# MSP432E411Y register map
Vendor: Texas Instruments; File version: 3.200
CPU: CM4 r1p2, little endian, no MPU, no FPU, 0x3 interrupt priority bits, 0x0 interrupts
Registers are 32-bit, read-write, no defined reset value unless marked. A register's access mark holds for its fields unless they carry their own. Offsets are from the block's base; [hi:lo] are bit positions; <NAME> marks a mode.

## UART0 — Register map for UART0 peripheral
Base 0x4000C000; register names take the prefix UART0
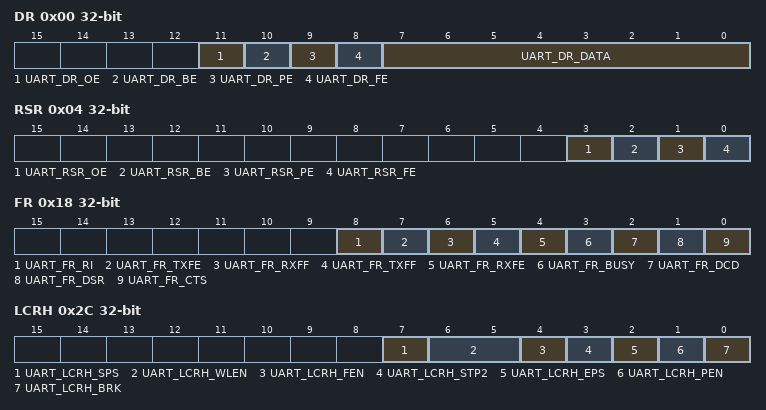
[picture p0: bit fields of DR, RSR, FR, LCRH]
0x00 DR — UART Data
  [11] UART_DR_OE — UART Overrun Error
  [10] UART_DR_BE — UART Break Error
  [9] UART_DR_PE — UART Parity Error
  [8] UART_DR_FE — UART Framing Error
  [7:0] UART_DR_DATA — Data Transmitted or Received
0x04 RSR — UART Receive Status/Error Clear
  [3] UART_RSR_OE — UART Overrun Error
  [2] UART_RSR_BE — UART Break Error
  [1] UART_RSR_PE — UART Parity Error
  [0] UART_RSR_FE — UART Framing Error
0x04 ECR (UART_ALT view) — UART Receive Status/Error Clear
  [7:0] UART_ECR_DATA — Error Clear
0x18 FR — UART Flag
  [8] UART_FR_RI — Ring Indicator
  [7] UART_FR_TXFE — UART Transmit FIFO Empty
  [6] UART_FR_RXFF — UART Receive FIFO Full
  [5] UART_FR_TXFF — UART Transmit FIFO Full
  [4] UART_FR_RXFE — UART Receive FIFO Empty
  [3] UART_FR_BUSY — UART Busy
  [2] UART_FR_DCD — Data Carrier Detect
  [1] UART_FR_DSR — Data Set Ready
  [0] UART_FR_CTS — Clear To Send
0x20 ILPR — UART IrDA Low-Power Register
  [7:0] UART_ILPR_ILPDVSR — IrDA Low-Power Divisor
0x24 IBRD — UART Integer Baud-Rate Divisor
  [15:0] UART_IBRD_DIVINT — Integer Baud-Rate Divisor
0x28 FBRD — UART Fractional Baud-Rate Divisor
  [5:0] UART_FBRD_DIVFRAC — Fractional Baud-Rate Divisor
0x2C LCRH — UART Line Control
  [7] UART_LCRH_SPS — UART Stick Parity Select
  [6:5] UART_LCRH_WLEN — UART Word Length
    0=5 bits (default); 1=6 bits; 2=7 bits; 3=8 bits
  [4] UART_LCRH_FEN — UART Enable FIFOs
  [3] UART_LCRH_STP2 — UART Two Stop Bits Select
  [2] UART_LCRH_EPS — UART Even Parity Select
  [1] UART_LCRH_PEN — UART Parity Enable
  [0] UART_LCRH_BRK — UART Send Break
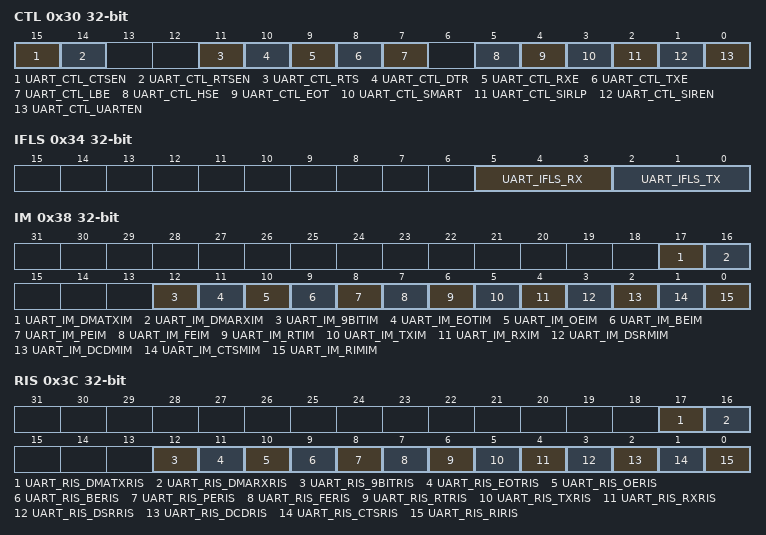
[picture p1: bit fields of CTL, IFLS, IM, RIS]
0x30 CTL — UART Control
  [15] UART_CTL_CTSEN — Enable Clear To Send
  [14] UART_CTL_RTSEN — Enable Request to Send
  [11] UART_CTL_RTS — Request to Send
  [10] UART_CTL_DTR — Data Terminal Ready
  [9] UART_CTL_RXE — UART Receive Enable
  [8] UART_CTL_TXE — UART Transmit Enable
  [7] UART_CTL_LBE — UART Loop Back Enable
  [5] UART_CTL_HSE — High-Speed Enable
  [4] UART_CTL_EOT — End of Transmission
  [3] UART_CTL_SMART — ISO 7816 Smart Card Support
  [2] UART_CTL_SIRLP — UART SIR Low-Power Mode
  [1] UART_CTL_SIREN — UART SIR Enable
  [0] UART_CTL_UARTEN — UART Enable
0x34 IFLS — UART Interrupt FIFO Level Select
  [5:3] UART_IFLS_RX — UART Receive Interrupt FIFO Level Select
    0=UART_IFLS_RX1_8 (RX FIFO >= 1/8 full); 1=UART_IFLS_RX2_8 (RX FIFO >= 1/4 full); 2=UART_IFLS_RX4_8 (RX FIFO >= 1/2 full (default)); 3=UART_IFLS_RX6_8 (RX FIFO >= 3/4 full); 4=UART_IFLS_RX7_8 (RX FIFO >= 7/8 full)
  [2:0] UART_IFLS_TX — UART Transmit Interrupt FIFO Level Select
    0=UART_IFLS_TX1_8 (TX FIFO <= 1/8 full); 1=UART_IFLS_TX2_8 (TX FIFO <= 1/4 full); 2=UART_IFLS_TX4_8 (TX FIFO <= 1/2 full (default)); 3=UART_IFLS_TX6_8 (TX FIFO <= 3/4 full); 4=UART_IFLS_TX7_8 (TX FIFO <= 7/8 full)
0x38 IM — UART Interrupt Mask
  [17] UART_IM_DMATXIM — Transmit DMA Interrupt Mask
  [16] UART_IM_DMARXIM — Receive DMA Interrupt Mask
  [12] UART_IM_9BITIM — 9-Bit Mode Interrupt Mask
  [11] UART_IM_EOTIM — End of Transmission Interrupt Mask
  [10] UART_IM_OEIM — UART Overrun Error Interrupt Mask
  [9] UART_IM_BEIM — UART Break Error Interrupt Mask
  [8] UART_IM_PEIM — UART Parity Error Interrupt Mask
  [7] UART_IM_FEIM — UART Framing Error Interrupt Mask
  [6] UART_IM_RTIM — UART Receive Time-Out Interrupt Mask
  [5] UART_IM_TXIM — UART Transmit Interrupt Mask
  [4] UART_IM_RXIM — UART Receive Interrupt Mask
  [3] UART_IM_DSRMIM — UART Data Set Ready Modem Interrupt Mask
  [2] UART_IM_DCDMIM — UART Data Carrier Detect Modem Interrupt Mask
  [1] UART_IM_CTSMIM — UART Clear to Send Modem Interrupt Mask
  [0] UART_IM_RIMIM — UART Ring Indicator Modem Interrupt Mask
0x3C RIS — UART Raw Interrupt Status
  [17] UART_RIS_DMATXRIS — Transmit DMA Raw Interrupt Status
  [16] UART_RIS_DMARXRIS — Receive DMA Raw Interrupt Status
  [12] UART_RIS_9BITRIS — 9-Bit Mode Raw Interrupt Status
  [11] UART_RIS_EOTRIS — End of Transmission Raw Interrupt Status
  [10] UART_RIS_OERIS — UART Overrun Error Raw Interrupt Status
  [9] UART_RIS_BERIS — UART Break Error Raw Interrupt Status
  [8] UART_RIS_PERIS — UART Parity Error Raw Interrupt Status
  [7] UART_RIS_FERIS — UART Framing Error Raw Interrupt Status
  [6] UART_RIS_RTRIS — UART Receive Time-Out Raw Interrupt Status
  [5] UART_RIS_TXRIS — UART Transmit Raw Interrupt Status
  [4] UART_RIS_RXRIS — UART Receive Raw Interrupt Status
  [3] UART_RIS_DSRRIS — UART Data Set Ready Modem Raw Interrupt Status
  [2] UART_RIS_DCDRIS — UART Data Carrier Detect Modem Raw Interrupt Status
  [1] UART_RIS_CTSRIS — UART Clear to Send Modem Raw Interrupt Status
  [0] UART_RIS_RIRIS — UART Ring Indicator Modem Raw Interrupt Status
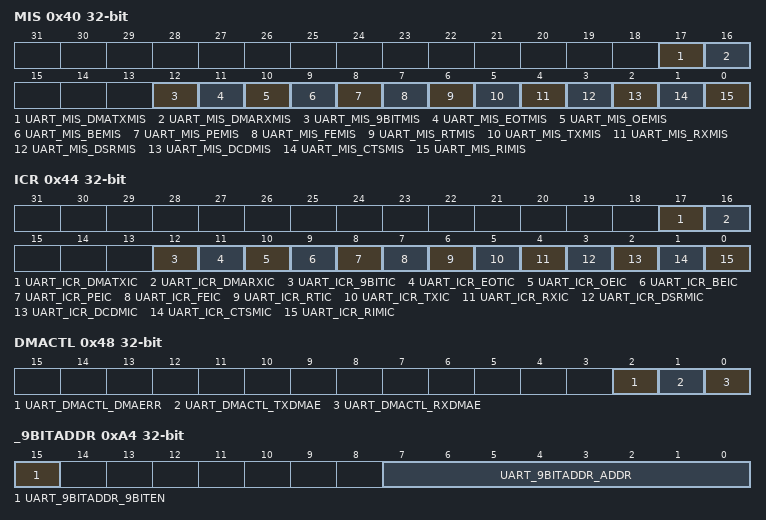
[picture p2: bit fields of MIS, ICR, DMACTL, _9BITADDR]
0x40 MIS — UART Masked Interrupt Status
  [17] UART_MIS_DMATXMIS — Transmit DMA Masked Interrupt Status
  [16] UART_MIS_DMARXMIS — Receive DMA Masked Interrupt Status
  [12] UART_MIS_9BITMIS — 9-Bit Mode Masked Interrupt Status
  [11] UART_MIS_EOTMIS — End of Transmission Masked Interrupt Status
  [10] UART_MIS_OEMIS — UART Overrun Error Masked Interrupt Status
  [9] UART_MIS_BEMIS — UART Break Error Masked Interrupt Status
  [8] UART_MIS_PEMIS — UART Parity Error Masked Interrupt Status
  [7] UART_MIS_FEMIS — UART Framing Error Masked Interrupt Status
  [6] UART_MIS_RTMIS — UART Receive Time-Out Masked Interrupt Status
  [5] UART_MIS_TXMIS — UART Transmit Masked Interrupt Status
  [4] UART_MIS_RXMIS — UART Receive Masked Interrupt Status
  [3] UART_MIS_DSRMIS — UART Data Set Ready Modem Masked Interrupt Status
  [2] UART_MIS_DCDMIS — UART Data Carrier Detect Modem Masked Interrupt Status
  [1] UART_MIS_CTSMIS — UART Clear to Send Modem Masked Interrupt Status
  [0] UART_MIS_RIMIS — UART Ring Indicator Modem Masked Interrupt Status
0x44 ICR wo — UART Interrupt Clear
  [17] UART_ICR_DMATXIC — Transmit DMA Interrupt Clear
  [16] UART_ICR_DMARXIC — Receive DMA Interrupt Clear
  [12] UART_ICR_9BITIC — 9-Bit Mode Interrupt Clear
  [11] UART_ICR_EOTIC — End of Transmission Interrupt Clear
  [10] UART_ICR_OEIC — Overrun Error Interrupt Clear
  [9] UART_ICR_BEIC — Break Error Interrupt Clear
  [8] UART_ICR_PEIC — Parity Error Interrupt Clear
  [7] UART_ICR_FEIC — Framing Error Interrupt Clear
  [6] UART_ICR_RTIC — Receive Time-Out Interrupt Clear
  [5] UART_ICR_TXIC — Transmit Interrupt Clear
  [4] UART_ICR_RXIC — Receive Interrupt Clear
  [3] UART_ICR_DSRMIC — UART Data Set Ready Modem Interrupt Clear
  [2] UART_ICR_DCDMIC — UART Data Carrier Detect Modem Interrupt Clear
  [1] UART_ICR_CTSMIC — UART Clear to Send Modem Interrupt Clear
  [0] UART_ICR_RIMIC — UART Ring Indicator Modem Interrupt Clear
0x48 DMACTL — UART DMA Control
  [2] UART_DMACTL_DMAERR — DMA on Error
  [1] UART_DMACTL_TXDMAE — Transmit DMA Enable
  [0] UART_DMACTL_RXDMAE — Receive DMA Enable
0xA4 _9BITADDR — UART 9-Bit Self Address
  [15] UART_9BITADDR_9BITEN — Enable 9-Bit Mode
  [7:0] UART_9BITADDR_ADDR — Self Address for 9-Bit Mode
0xA8 _9BITAMASK — UART 9-Bit Self Address Mask
  [7:0] UART_9BITAMASK_MASK — Self Address Mask for 9-Bit Mode
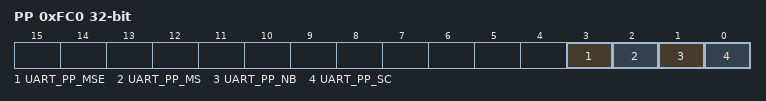
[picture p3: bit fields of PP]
0xFC0 PP — UART Peripheral Properties
  [3] UART_PP_MSE — Modem Support Extended
  [2] UART_PP_MS — Modem Support
  [1] UART_PP_NB — 9-Bit Support
  [0] UART_PP_SC — Smart Card Support
0xFC8 CC — UART Clock Configuration
  [3:0] UART_CC_CS — UART Baud Clock Source
    0=UART_CC_CS_SYSCLK (System clock (based on clock source and divisor factor)); 5=UART_CC_CS_PIOSC (PIOSC)

## UART1 — Register map for UART0 peripheral
Base 0x4000D000; register names take the prefix UART1
Registers as UART0.

## UART2 — Register map for UART0 peripheral
Base 0x4000E000; register names take the prefix UART2
Registers as UART0.

## UART3 — Register map for UART0 peripheral
Base 0x4000F000; register names take the prefix UART3
Registers as UART0.

## UART4 — Register map for UART0 peripheral
Base 0x40010000; register names take the prefix UART4
Registers as UART0.

## UART5 — Register map for UART0 peripheral
Base 0x40011000; register names take the prefix UART5
Registers as UART0.

## UART6 — Register map for UART0 peripheral
Base 0x40012000; register names take the prefix UART6
Registers as UART0.

## UART7 — Register map for UART0 peripheral
Base 0x40013000; register names take the prefix UART7
Registers as UART0.
